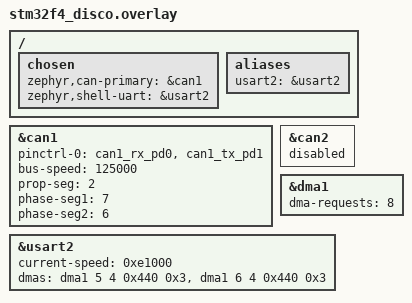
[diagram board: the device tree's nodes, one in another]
&can1 {
	status = "okay";
	pinctrl-0 = <&can1_rx_pd0 &can1_tx_pd1>;
	bus-speed = <125000>;

	// compatible = "st,stm32-can";
	// #address-cells = <1>;
	// #size-cells = <0>;
	// reg = <0x40006400 0x400>;
	// interrupts = <19 0>, <20 0>, <21 0>, <22 0>;
	// interrupt-names = "TX", "RX0", "RX1", "SCE";
	// clocks = <&rcc 2 0x02000000>;
	// status = "disabled";
	// label = "CAN_1";
	// bus-speed = <125000>;
	// sjw = <1>;
	prop-seg = <2>;
	phase-seg1 = <7>;
	phase-seg2 = <6>;
};

// compatible = "microchip,mcp2515";
// 		spi-max-frequency = <1000000>;
// 		int-gpios = <&arduino_header 8 GPIO_ACTIVE_LOW>; /* D2 */
// 		status = "okay";
// 		label = "CAN_1";
// 		reg = <0x0>;
// 		osc-freq = <16000000>;
// 		bus-speed = <125000>;
// 		sjw = <1>;
// 		prop-seg = <2>;
// 		phase-seg1 = <7>;
// 		phase-seg2 = <6>;
// 		#address-cells = <1>;
// 		#size-cells = <0>;


&can2 {
	status = "disabled";
};

&dma1 {
	status = "okay";
	dma-requests = <8>;
};

&usart2 {
	status = "okay";
	current-speed = < 0xe1000 >;
	dmas = <&dma1 5 4 0x440 0x3>,
	       <&dma1 6 4 0x440 0x3>;
	dma-names = "rx", "tx";
};

/ {

	chosen {
		zephyr,can-primary = &can1;
		zephyr,shell-uart = &usart2;
	};
	aliases {
		usart2 = &usart2;
	};

};

